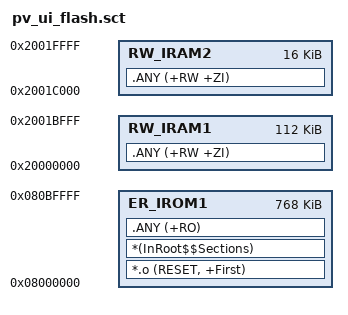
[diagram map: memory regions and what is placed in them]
; Keep sectors 10 and 11 out of firmware: two power-fail-safe settings journals.
LR_IROM1 0x08000000 0x000C0000 {
  ER_IROM1 0x08000000 0x000C0000 {
    *.o (RESET, +First)
    *(InRoot$$Sections)
    .ANY (+RO)
  }
  RW_IRAM1 0x20000000 0x0001C000 { .ANY (+RW +ZI) }
  RW_IRAM2 0x2001C000 0x00004000 { .ANY (+RW +ZI) }
}
